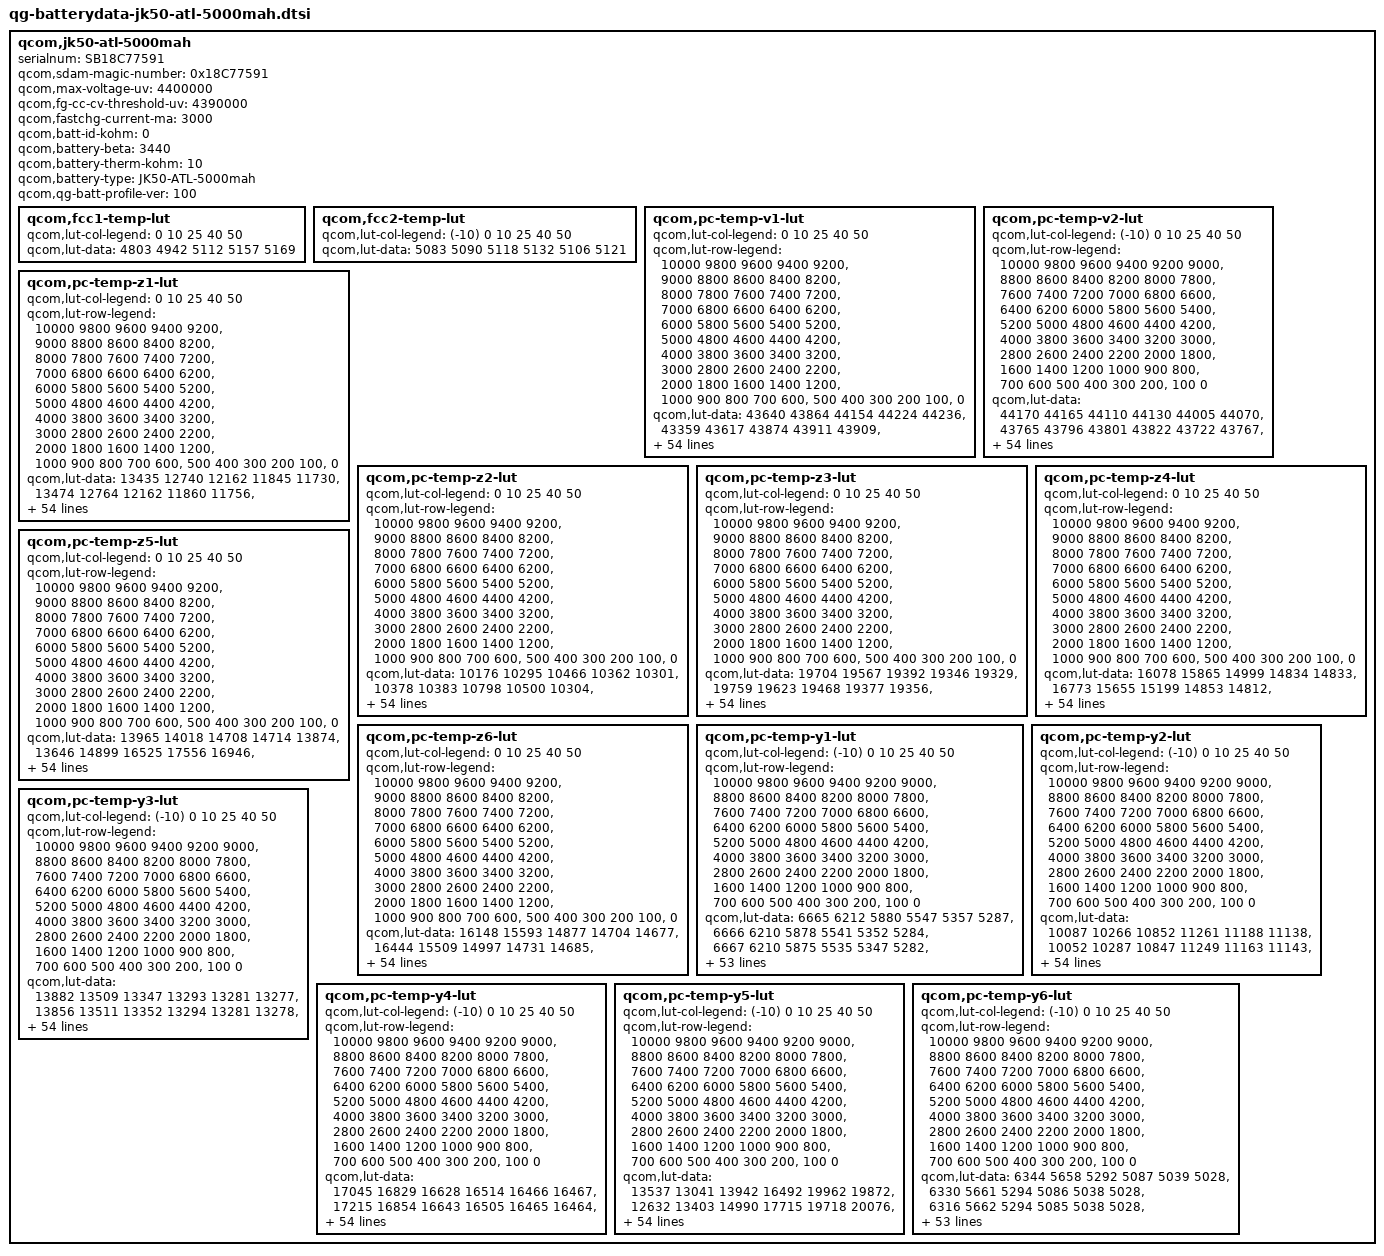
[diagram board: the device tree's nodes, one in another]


qcom,jk50-atl-5000mah {
    /* 4984199_Lenovo_Ibiza_5000mAH_PM7250B_averaged_MasterSlave_Dec17th2020 */
    serialnum = "SB18C77591";
    qcom,sdam-magic-number = <0x18C77591>;
    qcom,max-voltage-uv = <4400000>;
    qcom,fg-cc-cv-threshold-uv = <4390000>;
    qcom,fastchg-current-ma = <3000>;
    qcom,batt-id-kohm = <0>;
    qcom,battery-beta = <3440>;
    qcom,battery-therm-kohm = <10>;
    qcom,battery-type = "JK50-ATL-5000mah";
    qcom,qg-batt-profile-ver = <100>;

	qcom,fcc1-temp-lut {
		qcom,lut-col-legend = <0 10 25 40 50>;
		qcom,lut-data = <4803 4942 5112 5157 5169>;
	};

	qcom,fcc2-temp-lut {
		qcom,lut-col-legend = <(-10) 0 10 25 40 50>;
		qcom,lut-data = <5083 5090 5118 5132 5106 5121>;
	};

	qcom,pc-temp-v1-lut {
		qcom,lut-col-legend = <0 10 25 40 50>;
		qcom,lut-row-legend = <10000 9800 9600 9400 9200>,
			<9000 8800 8600 8400 8200>,
			<8000 7800 7600 7400 7200>,
			<7000 6800 6600 6400 6200>,
			<6000 5800 5600 5400 5200>,
			<5000 4800 4600 4400 4200>,
			<4000 3800 3600 3400 3200>,
			<3000 2800 2600 2400 2200>,
			<2000 1800 1600 1400 1200>,
			<1000 900 800 700 600>,
			<500 400 300 200 100>,
			<0>;
		qcom,lut-data = <43640 43864 44154 44224 44236>,
			<43359 43617 43874 43911 43909>,
			<43118 43373 43622 43662 43662>,
			<42886 43132 43397 43433 43432>,
			<42648 42893 43162 43205 43203>,
			<42411 42655 42918 42968 42971>,
			<42181 42419 42675 42731 42737>,
			<41959 42186 42435 42492 42501>,
			<41742 41959 42197 42254 42265>,
			<41532 41737 41963 42018 42029>,
			<41329 41519 41732 41784 41796>,
			<41130 41305 41506 41554 41565>,
			<40936 41098 41287 41330 41339>,
			<40742 40901 41073 41110 41115>,
			<40529 40708 40863 40897 40900>,
			<40281 40503 40657 40691 40694>,
			<40052 40272 40455 40489 40495>,
			<39883 40059 40250 40290 40302>,
			<39743 39894 40057 40097 40114>,
			<39611 39753 39892 39925 39938>,
			<39481 39613 39742 39776 39780>,
			<39358 39477 39577 39603 39603>,
			<39237 39334 39392 39336 39350>,
			<39120 39160 39194 39056 39082>,
			<39007 38964 38961 38883 38907>,
			<38896 38792 38723 38760 38784>,
			<38790 38635 38590 38655 38676>,
			<38691 38508 38516 38561 38575>,
			<38598 38431 38454 38476 38484>,
			<38512 38374 38389 38395 38396>,
			<38438 38327 38328 38320 38315>,
			<38371 38285 38273 38251 38241>,
			<38315 38248 38223 38188 38172>,
			<38269 38214 38175 38128 38106>,
			<38228 38183 38129 38069 38040>,
			<38189 38149 38085 38011 37974>,
			<38153 38115 38039 37957 37911>,
			<38112 38076 37994 37910 37854>,
			<38058 38018 37934 37850 37785>,
			<37991 37935 37848 37756 37687>,
			<37906 37836 37743 37642 37571>,
			<37783 37717 37630 37530 37456>,
			<37643 37579 37500 37408 37333>,
			<37483 37416 37341 37253 37180>,
			<37336 37268 37191 37103 37036>,
			<37255 37172 37089 37008 36945>,
			<37222 37144 37062 36978 36914>,
			<37192 37120 37043 36958 36896>,
			<37166 37105 37023 36941 36876>,
			<37112 37062 36982 36889 36813>,
			<36906 36840 36763 36650 36550>,
			<36454 36403 36336 36215 36108>,
			<35874 35828 35761 35637 35529>,
			<35087 35044 34973 34850 34734>,
			<33840 33803 33746 33622 33492>,
			<30000 30000 30000 30000 30000>;
	};

	qcom,pc-temp-v2-lut {
		qcom,lut-col-legend = <(-10) 0 10 25 40 50>;
		qcom,lut-row-legend = <10000 9800 9600 9400 9200 9000>,
			<8800 8600 8400 8200 8000 7800>,
			<7600 7400 7200 7000 6800 6600>,
			<6400 6200 6000 5800 5600 5400>,
			<5200 5000 4800 4600 4400 4200>,
			<4000 3800 3600 3400 3200 3000>,
			<2800 2600 2400 2200 2000 1800>,
			<1600 1400 1200 1000 900 800>,
			<700 600 500 400 300 200>,
			<100 0>;
		qcom,lut-data = <44170 44165 44110 44130 44005 44070>,
			<43765 43796 43801 43822 43722 43767>,
			<43400 43460 43513 43537 43454 43486>,
			<43080 43166 43247 43277 43204 43230>,
			<42796 42906 43003 43040 42971 42998>,
			<42537 42653 42761 42805 42738 42767>,
			<42310 42395 42514 42564 42500 42529>,
			<42090 42144 42270 42324 42261 42290>,
			<41826 41913 42032 42087 42026 42054>,
			<41525 41697 41798 41852 41793 41819>,
			<41297 41479 41569 41620 41563 41587>,
			<41169 41245 41342 41388 41335 41359>,
			<41045 41022 41124 41164 41112 41136>,
			<40828 40848 40928 40955 40900 40918>,
			<40504 40701 40744 40755 40696 40705>,
			<40180 40494 40537 40546 40490 40499>,
			<39836 40122 40297 40322 40278 40299>,
			<39535 39757 40054 40110 40077 40108>,
			<39347 39549 39821 39933 39905 39932>,
			<39205 39392 39595 39765 39743 39761>,
			<39047 39225 39385 39564 39559 39579>,
			<38862 39043 39188 39326 39343 39382>,
			<38687 38871 39008 39104 39131 39182>,
			<38537 38720 38844 38913 38930 38967>,
			<38402 38579 38694 38743 38743 38760>,
			<38298 38435 38561 38605 38598 38610>,
			<38217 38280 38439 38488 38481 38492>,
			<38147 38158 38330 38382 38377 38386>,
			<38082 38082 38232 38283 38280 38286>,
			<38022 38023 38139 38192 38191 38194>,
			<37964 37969 38050 38109 38111 38113>,
			<37908 37920 37965 38034 38039 38038>,
			<37852 37873 37897 37963 37969 37967>,
			<37794 37827 37845 37897 37904 37902>,
			<37736 37783 37801 37834 37837 37834>,
			<37676 37737 37759 37772 37755 37741>,
			<37613 37689 37719 37710 37663 37632>,
			<37547 37635 37674 37642 37572 37528>,
			<37475 37572 37620 37569 37483 37429>,
			<37400 37499 37557 37491 37395 37335>,
			<37328 37418 37475 37409 37312 37251>,
			<37257 37323 37373 37316 37224 37164>,
			<37182 37208 37244 37197 37105 37050>,
			<37108 37081 37108 37064 36975 36918>,
			<37035 36960 36959 36930 36857 36800>,
			<36935 36860 36879 36878 36821 36764>,
			<36883 36818 36850 36862 36807 36750>,
			<36821 36779 36824 36843 36791 36737>,
			<36745 36724 36781 36810 36760 36704>,
			<36623 36634 36699 36721 36652 36588>,
			<36390 36415 36472 36439 36293 36232>,
			<35985 35976 35996 35931 35776 35710>,
			<35372 35340 35336 35272 35089 35023>,
			<34458 34431 34436 34348 34107 34043>,
			<32987 32935 33138 33029 32671 32707>,
			<28320 27840 27870 27984 28103 27815>;
	};

	qcom,pc-temp-z1-lut {
		qcom,lut-col-legend = <0 10 25 40 50>;
		qcom,lut-row-legend = <10000 9800 9600 9400 9200>,
			<9000 8800 8600 8400 8200>,
			<8000 7800 7600 7400 7200>,
			<7000 6800 6600 6400 6200>,
			<6000 5800 5600 5400 5200>,
			<5000 4800 4600 4400 4200>,
			<4000 3800 3600 3400 3200>,
			<3000 2800 2600 2400 2200>,
			<2000 1800 1600 1400 1200>,
			<1000 900 800 700 600>,
			<500 400 300 200 100>,
			<0>;
		qcom,lut-data = <13435 12740 12162 11845 11730>,
			<13474 12764 12162 11860 11756>,
			<13445 12773 12156 11854 11754>,
			<13418 12765 12154 11847 11752>,
			<13418 12748 12150 11842 11751>,
			<13427 12731 12136 11836 11749>,
			<13431 12709 12121 11831 11748>,
			<13434 12694 12108 11828 11748>,
			<13434 12690 12095 11826 11749>,
			<13418 12686 12086 11825 11751>,
			<13377 12681 12078 11826 11755>,
			<13347 12669 12075 11828 11761>,
			<13337 12657 12076 11831 11765>,
			<13330 12638 12077 11836 11768>,
			<13316 12608 12076 11837 11769>,
			<13278 12593 12073 11836 11769>,
			<13245 12584 12072 11835 11770>,
			<13235 12580 12071 11835 11771>,
			<13226 12582 12071 11836 11772>,
			<13224 12587 12073 11838 11774>,
			<13229 12594 12079 11841 11775>,
			<13235 12603 12083 11843 11777>,
			<13227 12611 12086 11844 11777>,
			<13195 12618 12089 11845 11778>,
			<13173 12625 12092 11846 11779>,
			<13175 12632 12096 11848 11781>,
			<13183 12638 12099 11850 11784>,
			<13192 12642 12103 11854 11786>,
			<13204 12642 12107 11857 11789>,
			<13214 12641 12112 11861 11792>,
			<13220 12640 12117 11866 11795>,
			<13229 12642 12124 11870 11799>,
			<13237 12646 12131 11875 11803>,
			<13241 12654 12140 11880 11807>,
			<13242 12671 12148 11886 11812>,
			<13243 12683 12156 11892 11817>,
			<13245 12689 12164 11898 11822>,
			<13247 12694 12170 11903 11825>,
			<13251 12705 12178 11908 11829>,
			<13261 12726 12189 11914 11832>,
			<13274 12741 12199 11919 11836>,
			<13297 12747 12205 11924 11840>,
			<13326 12755 12210 11930 11844>,
			<13362 12774 12225 11936 11848>,
			<13381 12795 12239 11944 11852>,
			<13355 12786 12250 11951 11856>,
			<13331 12789 12246 11951 11856>,
			<13311 12788 12245 11952 11858>,
			<13321 12783 12251 11954 11861>,
			<13369 12798 12256 11959 11864>,
			<13378 12821 12262 11965 11869>,
			<13406 12809 12280 11975 11876>,
			<13378 12851 12295 11985 11887>,
			<13451 12865 12319 12005 11904>,
			<13451 12865 12319 12005 11904>,
			<13451 12865 12319 12005 11904>;
	};

	qcom,pc-temp-z2-lut {
		qcom,lut-col-legend = <0 10 25 40 50>;
		qcom,lut-row-legend = <10000 9800 9600 9400 9200>,
			<9000 8800 8600 8400 8200>,
			<8000 7800 7600 7400 7200>,
			<7000 6800 6600 6400 6200>,
			<6000 5800 5600 5400 5200>,
			<5000 4800 4600 4400 4200>,
			<4000 3800 3600 3400 3200>,
			<3000 2800 2600 2400 2200>,
			<2000 1800 1600 1400 1200>,
			<1000 900 800 700 600>,
			<500 400 300 200 100>,
			<0>;
		qcom,lut-data = <10176 10295 10466 10362 10301>,
			<10378 10383 10798 10500 10304>,
			<10380 10420 10592 10668 10626>,
			<10378 10401 10568 10655 10663>,
			<10367 10367 10539 10637 10674>,
			<10346 10351 10505 10607 10655>,
			<10337 10342 10473 10567 10610>,
			<10343 10336 10445 10533 10568>,
			<10351 10332 10420 10501 10522>,
			<10355 10329 10396 10474 10489>,
			<10357 10322 10371 10449 10470>,
			<10355 10309 10361 10432 10457>,
			<10345 10298 10362 10430 10461>,
			<10325 10342 10366 10436 10479>,
			<10304 10422 10376 10443 10481>,
			<10276 10431 10403 10466 10386>,
			<10256 10353 10446 10482 10295>,
			<10254 10295 10697 10477 10305>,
			<10254 10307 10942 10462 10340>,
			<10254 10335 10852 10440 10369>,
			<10254 10362 10592 10399 10388>,
			<10254 10387 10522 10377 10420>,
			<10251 10414 10594 10546 10600>,
			<10243 10450 10651 10771 10838>,
			<10238 10490 10641 10731 10809>,
			<10240 10505 10617 10495 10538>,
			<10244 10507 10602 10393 10404>,
			<10250 10508 10588 10403 10423>,
			<10259 10508 10580 10419 10454>,
			<10270 10508 10596 10434 10481>,
			<10280 10509 10624 10453 10509>,
			<10291 10510 10637 10484 10514>,
			<10302 10511 10644 10543 10486>,
			<10312 10514 10649 10602 10458>,
			<10322 10520 10657 10643 10461>,
			<10332 10526 10665 10675 10476>,
			<10341 10532 10668 10670 10476>,
			<10352 10538 10672 10627 10462>,
			<10368 10548 10677 10604 10460>,
			<10388 10561 10698 10666 10510>,
			<10409 10576 10720 10742 10572>,
			<10431 10588 10728 10742 10585>,
			<10467 10604 10732 10724 10582>,
			<10540 10636 10740 10719 10575>,
			<10927 10834 10788 10701 10573>,
			<10827 10953 10874 10643 10585>,
			<10714 10955 10855 10653 10594>,
			<10710 10971 10840 10619 10570>,
			<10612 11105 10843 10647 10587>,
			<10565 11219 10879 10760 10685>,
			<10513 11089 10912 10734 10594>,
			<10504 11071 10878 10516 10330>,
			<10298 10924 10757 10430 10257>,
			<10059 10722 10666 10396 10206>,
			<10059 10722 10666 10396 10206>,
			<10059 10722 10666 10396 10206>;
	};

	qcom,pc-temp-z3-lut {
		qcom,lut-col-legend = <0 10 25 40 50>;
		qcom,lut-row-legend = <10000 9800 9600 9400 9200>,
			<9000 8800 8600 8400 8200>,
			<8000 7800 7600 7400 7200>,
			<7000 6800 6600 6400 6200>,
			<6000 5800 5600 5400 5200>,
			<5000 4800 4600 4400 4200>,
			<4000 3800 3600 3400 3200>,
			<3000 2800 2600 2400 2200>,
			<2000 1800 1600 1400 1200>,
			<1000 900 800 700 600>,
			<500 400 300 200 100>,
			<0>;
		qcom,lut-data = <19704 19567 19392 19346 19329>,
			<19759 19623 19468 19377 19356>,
			<19701 19650 19488 19411 19385>,
			<19648 19652 19490 19417 19397>,
			<19638 19654 19492 19420 19403>,
			<19634 19653 19494 19422 19406>,
			<19633 19646 19495 19423 19408>,
			<19636 19636 19492 19423 19409>,
			<19640 19626 19485 19421 19408>,
			<19643 19616 19480 19419 19408>,
			<19646 19609 19475 19418 19406>,
			<19649 19604 19469 19415 19403>,
			<19650 19600 19464 19410 19400>,
			<19651 19596 19458 19400 19394>,
			<19655 19590 19449 19394 19388>,
			<19671 19585 19439 19390 19379>,
			<19685 19570 19434 19386 19370>,
			<19680 19554 19440 19384 19366>,
			<19667 19541 19446 19381 19363>,
			<19658 19527 19438 19375 19359>,
			<19653 19520 19421 19365 19352>,
			<19650 19517 19415 19359 19348>,
			<19652 19515 19423 19369 19354>,
			<19664 19523 19429 19381 19361>,
			<19674 19541 19429 19379 19359>,
			<19682 19549 19428 19364 19342>,
			<19689 19549 19426 19354 19331>,
			<19691 19549 19420 19350 19327>,
			<19689 19548 19416 19348 19326>,
			<19687 19544 19415 19348 19327>,
			<19683 19539 19415 19351 19330>,
			<19678 19534 19415 19353 19334>,
			<19671 19528 19416 19358 19341>,
			<19663 19523 19417 19363 19348>,
			<19653 19518 19419 19370 19354>,
			<19642 19514 19421 19377 19359>,
			<19631 19510 19421 19376 19359>,
			<19621 19506 19419 19368 19352>,
			<19611 19504 19417 19363 19347>,
			<19602 19502 19415 19363 19345>,
			<19595 19500 19413 19363 19344>,
			<19591 19495 19409 19362 19344>,
			<19584 19488 19405 19359 19347>,
			<19568 19482 19401 19358 19348>,
			<19503 19453 19392 19355 19347>,
			<19369 19424 19379 19342 19334>,
			<19330 19413 19374 19340 19332>,
			<19324 19410 19370 19339 19325>,
			<19309 19353 19370 19332 19321>,
			<19306 19331 19352 19324 19317>,
			<19310 19401 19354 19329 19334>,
			<19329 19391 19351 19355 19356>,
			<19336 19363 19351 19359 19355>,
			<19342 19322 19350 19351 19351>,
			<19342 19322 19350 19351 19351>,
			<19342 19322 19350 19351 19351>;
	};

	qcom,pc-temp-z4-lut {
		qcom,lut-col-legend = <0 10 25 40 50>;
		qcom,lut-row-legend = <10000 9800 9600 9400 9200>,
			<9000 8800 8600 8400 8200>,
			<8000 7800 7600 7400 7200>,
			<7000 6800 6600 6400 6200>,
			<6000 5800 5600 5400 5200>,
			<5000 4800 4600 4400 4200>,
			<4000 3800 3600 3400 3200>,
			<3000 2800 2600 2400 2200>,
			<2000 1800 1600 1400 1200>,
			<1000 900 800 700 600>,
			<500 400 300 200 100>,
			<0>;
		qcom,lut-data = <16078 15865 14999 14834 14833>,
			<16773 15655 15199 14853 14812>,
			<16522 15477 15191 14942 14872>,
			<16217 15324 15060 14899 14849>,
			<16011 15195 14973 14855 14820>,
			<15829 15100 14917 14827 14800>,
			<15678 15026 14873 14804 14781>,
			<15552 14967 14838 14784 14765>,
			<15445 14920 14809 14766 14750>,
			<15360 14882 14786 14750 14736>,
			<15291 14849 14765 14733 14722>,
			<15228 14821 14747 14719 14709>,
			<15164 14796 14730 14710 14700>,
			<15105 14764 14716 14703 14693>,
			<15061 14732 14709 14696 14689>,
			<15028 14723 14706 14688 14687>,
			<14999 14729 14700 14681 14686>,
			<14971 14733 14679 14676 14682>,
			<14944 14727 14659 14672 14675>,
			<14919 14718 14657 14669 14671>,
			<14896 14710 14662 14665 14667>,
			<14874 14702 14669 14664 14665>,
			<14849 14696 14676 14699 14696>,
			<14820 14700 14688 14752 14749>,
			<14794 14713 14728 14776 14775>,
			<14773 14727 14787 14792 14792>,
			<14755 14750 14800 14796 14797>,
			<14746 14767 14790 14790 14792>,
			<14742 14766 14777 14780 14782>,
			<14739 14757 14766 14769 14772>,
			<14737 14747 14753 14755 14757>,
			<14736 14738 14740 14740 14741>,
			<14735 14729 14727 14723 14721>,
			<14732 14720 14715 14707 14702>,
			<14729 14712 14702 14690 14685>,
			<14727 14704 14690 14677 14672>,
			<14725 14697 14683 14672 14669>,
			<14723 14691 14678 14671 14668>,
			<14720 14690 14676 14670 14668>,
			<14717 14689 14682 14678 14678>,
			<14715 14689 14688 14687 14691>,
			<14713 14690 14687 14687 14690>,
			<14710 14691 14686 14684 14682>,
			<14702 14688 14685 14683 14682>,
			<14692 14673 14677 14679 14678>,
			<14803 14668 14658 14664 14662>,
			<14844 14673 14654 14659 14659>,
			<14847 14670 14648 14648 14652>,
			<14858 14726 14637 14637 14634>,
			<14852 14745 14650 14638 14630>,
			<14846 14671 14667 14660 14646>,
			<14847 14699 14684 14651 14644>,
			<14858 14739 14690 14653 14649>,
			<14870 14793 14696 14665 14658>,
			<14870 14793 14696 14665 14658>,
			<14870 14793 14696 14665 14658>;
	};

	qcom,pc-temp-z5-lut {
		qcom,lut-col-legend = <0 10 25 40 50>;
		qcom,lut-row-legend = <10000 9800 9600 9400 9200>,
			<9000 8800 8600 8400 8200>,
			<8000 7800 7600 7400 7200>,
			<7000 6800 6600 6400 6200>,
			<6000 5800 5600 5400 5200>,
			<5000 4800 4600 4400 4200>,
			<4000 3800 3600 3400 3200>,
			<3000 2800 2600 2400 2200>,
			<2000 1800 1600 1400 1200>,
			<1000 900 800 700 600>,
			<500 400 300 200 100>,
			<0>;
		qcom,lut-data = <13965 14018 14708 14714 13874>,
			<13646 14899 16525 17556 16946>,
			<13758 15591 17147 18406 18349>,
			<13933 16076 17498 19062 19760>,
			<14180 16479 17982 19635 20965>,
			<14542 16905 18692 20075 21571>,
			<14869 17340 19325 20467 22024>,
			<15158 17765 19790 20879 22559>,
			<15410 18147 20228 21296 23152>,
			<15590 18546 20621 21841 23842>,
			<15734 19134 21231 22865 24749>,
			<15839 20132 21929 23808 25769>,
			<15894 21138 22987 24072 26838>,
			<15940 23127 23946 24193 27981>,
			<16100 25816 24050 24468 28307>,
			<16736 26283 23945 25312 27155>,
			<17256 25497 24227 26452 26035>,
			<17213 24967 31015 28040 26735>,
			<17054 24850 38195 29709 28556>,
			<16995 24655 37014 29924 29628>,
			<17208 24696 32389 29329 30074>,
			<17630 26253 32949 29010 30757>,
			<18358 29283 45186 39916 35874>,
			<20045 40149 55207 54482 42763>,
			<22268 60347 54498 51773 40945>,
			<25604 65535 51766 35614 28789>,
			<29844 65535 47811 26141 21313>,
			<33454 63513 40372 23210 19427>,
			<36965 59705 34528 21662 18465>,
			<39497 53865 32081 21269 18364>,
			<40530 49066 30555 21058 18358>,
			<41212 45483 30389 21122 18493>,
			<41350 42578 30613 22319 19811>,
			<39740 40368 30999 24348 21987>,
			<37257 38525 33398 29507 26441>,
			<35146 37656 36902 35990 31960>,
			<32574 37358 39259 36772 32989>,
			<30651 37201 41389 35012 32705>,
			<29600 37605 42132 34045 32265>,
			<28873 39120 41386 34290 31436>,
			<28896 39890 40045 34586 30180>,
			<30293 37272 36996 32363 28281>,
			<31856 34776 32519 26956 26046>,
			<33377 34945 31446 26600 26436>,
			<31464 35539 31361 26689 26668>,
			<15864 30495 31786 24225 23147>,
			<13240 25744 29517 23582 22029>,
			<13028 25005 27866 24554 20780>,
			<12594 15928 29916 24017 23361>,
			<12573 14407 23543 22150 22767>,
			<12817 24233 21320 19790 23926>,
			<13203 19238 18059 22759 25956>,
			<13000 15863 17006 21908 22723>,
			<12785 13018 16149 18004 18844>,
			<12785 13018 16149 18004 18844>,
			<12785 13018 16149 18004 18844>;
	};

	qcom,pc-temp-z6-lut {
		qcom,lut-col-legend = <0 10 25 40 50>;
		qcom,lut-row-legend = <10000 9800 9600 9400 9200>,
			<9000 8800 8600 8400 8200>,
			<8000 7800 7600 7400 7200>,
			<7000 6800 6600 6400 6200>,
			<6000 5800 5600 5400 5200>,
			<5000 4800 4600 4400 4200>,
			<4000 3800 3600 3400 3200>,
			<3000 2800 2600 2400 2200>,
			<2000 1800 1600 1400 1200>,
			<1000 900 800 700 600>,
			<500 400 300 200 100>,
			<0>;
		qcom,lut-data = <16148 15593 14877 14704 14677>,
			<16444 15509 14997 14731 14685>,
			<16268 15429 15000 14784 14724>,
			<16060 15350 14940 14769 14720>,
			<15933 15277 14900 14752 14713>,
			<15827 15218 14874 14740 14707>,
			<15741 15170 14852 14730 14700>,
			<15670 15129 14831 14721 14693>,
			<15612 15095 14814 14713 14687>,
			<15565 15065 14799 14705 14681>,
			<15528 15042 14786 14697 14676>,
			<15491 15024 14774 14691 14670>,
			<15445 15007 14764 14683 14664>,
			<15400 14983 14754 14676 14658>,
			<15371 14959 14746 14670 14653>,
			<15354 14943 14739 14663 14647>,
			<15338 14935 14732 14658 14642>,
			<15318 14927 14727 14654 14637>,
			<15297 14917 14722 14651 14633>,
			<15279 14908 14716 14646 14628>,
			<15264 14902 14710 14639 14623>,
			<15251 14899 14709 14635 14620>,
			<15241 14897 14715 14657 14638>,
			<15232 14903 14726 14687 14666>,
			<15225 14919 14745 14691 14670>,
			<15219 14933 14769 14691 14669>,
			<15214 14944 14774 14690 14668>,
			<15211 14952 14768 14687 14665>,
			<15209 14951 14762 14681 14660>,
			<15207 14946 14757 14677 14656>,
			<15206 14941 14752 14673 14652>,
			<15205 14935 14748 14669 14649>,
			<15203 14930 14744 14665 14644>,
			<15200 14926 14740 14662 14640>,
			<15195 14922 14738 14660 14638>,
			<15191 14919 14735 14658 14635>,
			<15187 14917 14733 14656 14633>,
			<15185 14916 14732 14651 14629>,
			<15186 14916 14731 14650 14628>,
			<15189 14920 14734 14653 14631>,
			<15193 14923 14738 14658 14636>,
			<15200 14926 14738 14658 14636>,
			<15203 14928 14737 14656 14635>,
			<15205 14930 14737 14656 14636>,
			<15180 14920 14733 14654 14634>,
			<15168 14907 14721 14641 14621>,
			<15165 14903 14717 14638 14619>,
			<15163 14901 14712 14633 14612>,
			<15161 14897 14708 14625 14603>,
			<15163 14898 14706 14622 14599>,
			<15171 14907 14716 14635 14615>,
			<15189 14920 14726 14647 14629>,
			<15209 14931 14733 14653 14634>,
			<15237 14949 14742 14658 14639>,
			<15237 14949 14742 14658 14639>,
			<15237 14949 14742 14658 14639>;
	};

	qcom,pc-temp-y1-lut {
		qcom,lut-col-legend = <(-10) 0 10 25 40 50>;
		qcom,lut-row-legend = <10000 9800 9600 9400 9200 9000>,
			<8800 8600 8400 8200 8000 7800>,
			<7600 7400 7200 7000 6800 6600>,
			<6400 6200 6000 5800 5600 5400>,
			<5200 5000 4800 4600 4400 4200>,
			<4000 3800 3600 3400 3200 3000>,
			<2800 2600 2400 2200 2000 1800>,
			<1600 1400 1200 1000 900 800>,
			<700 600 500 400 300 200>,
			<100 0>;
		qcom,lut-data = <6665 6212 5880 5547 5357 5287>,
			<6666 6210 5878 5541 5352 5284>,
			<6667 6210 5875 5535 5347 5282>,
			<6668 6210 5872 5530 5342 5279>,
			<6669 6212 5869 5524 5338 5277>,
			<6669 6214 5867 5519 5334 5275>,
			<6672 6217 5866 5514 5331 5272>,
			<6676 6221 5865 5510 5328 5271>,
			<6676 6220 5861 5505 5325 5269>,
			<6671 6218 5853 5502 5322 5268>,
			<6670 6217 5849 5498 5319 5267>,
			<6670 6217 5849 5495 5318 5266>,
			<6671 6218 5849 5493 5316 5264>,
			<6673 6220 5847 5490 5315 5263>,
			<6675 6226 5844 5488 5314 5263>,
			<6678 6231 5843 5488 5313 5262>,
			<6685 6238 5847 5488 5313 5263>,
			<6691 6242 5851 5488 5313 5263>,
			<6688 6243 5853 5489 5313 5264>,
			<6683 6243 5855 5490 5314 5264>,
			<6681 6243 5855 5492 5315 5265>,
			<6681 6243 5854 5492 5315 5266>,
			<6680 6242 5854 5494 5316 5266>,
			<6670 6241 5854 5496 5318 5267>,
			<6648 6238 5853 5500 5319 5268>,
			<6643 6238 5855 5503 5321 5270>,
			<6656 6237 5860 5506 5324 5271>,
			<6665 6237 5864 5510 5327 5273>,
			<6657 6236 5867 5515 5330 5275>,
			<6646 6235 5869 5519 5333 5278>,
			<6646 6235 5871 5524 5336 5280>,
			<6657 6237 5874 5529 5340 5283>,
			<6662 6239 5875 5534 5343 5286>,
			<6661 6233 5875 5539 5347 5288>,
			<6659 6226 5876 5544 5350 5290>,
			<6656 6225 5878 5548 5353 5292>,
			<6653 6225 5881 5552 5355 5294>,
			<6651 6225 5883 5554 5357 5295>,
			<6649 6224 5887 5556 5358 5297>,
			<6647 6222 5889 5558 5360 5299>,
			<6642 6223 5889 5559 5362 5300>,
			<6635 6225 5890 5561 5363 5301>,
			<6633 6225 5899 5568 5366 5303>,
			<6630 6226 5903 5578 5370 5305>,
			<6635 6241 5910 5579 5374 5310>,
			<6682 6248 5913 5589 5379 5313>,
			<6682 6244 5914 5592 5380 5312>,
			<6688 6258 5915 5595 5379 5313>,
			<6690 6241 5916 5595 5379 5312>,
			<6693 6238 5919 5595 5380 5313>,
			<6708 6254 5928 5599 5384 5317>,
			<6703 6268 5930 5613 5391 5323>,
			<6708 6264 5946 5634 5403 5332>,
			<6718 6292 5969 5656 5417 5343>,
			<6718 6292 5969 5656 5417 5343>,
			<6718 6292 5969 5656 5417 5343>;
	};

	qcom,pc-temp-y2-lut {
		qcom,lut-col-legend = <(-10) 0 10 25 40 50>;
		qcom,lut-row-legend = <10000 9800 9600 9400 9200 9000>,
			<8800 8600 8400 8200 8000 7800>,
			<7600 7400 7200 7000 6800 6600>,
			<6400 6200 6000 5800 5600 5400>,
			<5200 5000 4800 4600 4400 4200>,
			<4000 3800 3600 3400 3200 3000>,
			<2800 2600 2400 2200 2000 1800>,
			<1600 1400 1200 1000 900 800>,
			<700 600 500 400 300 200>,
			<100 0>;
		qcom,lut-data = <10087 10266 10852 11261 11188 11138>,
			<10052 10287 10847 11249 11163 11143>,
			<10042 10317 10841 11233 11125 11132>,
			<10053 10350 10837 11212 11085 11111>,
			<10077 10378 10832 11190 11052 11083>,
			<10109 10396 10828 11165 11037 11054>,
			<10152 10410 10823 11133 11034 11009>,
			<10213 10421 10820 11104 11032 10966>,
			<10327 10421 10823 11090 11016 10951>,
			<10519 10421 10828 11080 10980 10946>,
			<10598 10444 10832 11078 10959 10946>,
			<10539 10596 10837 11093 10957 10956>,
			<10473 10761 10845 11108 10964 10962>,
			<10528 10792 10879 11106 10992 10950>,
			<10701 10796 10957 11102 11047 10932>,
			<10738 10796 11025 11110 11094 10936>,
			<10220 10818 11097 11169 11133 11022>,
			<9713 10852 11141 11242 11176 11116>,
			<9684 10908 11142 11318 11245 11161>,
			<9680 10995 11140 11385 11334 11200>,
			<9677 11059 11146 11387 11390 11280>,
			<9674 11114 11173 11342 11432 11448>,
			<9672 11143 11203 11317 11452 11540>,
			<9671 11123 11230 11336 11389 11391>,
			<9670 11065 11260 11366 11285 11185>,
			<9669 10962 11291 11388 11261 11165>,
			<9668 10695 11323 11412 11276 11201>,
			<9667 10488 11347 11437 11285 11239>,
			<9666 10429 11365 11472 11313 11281>,
			<9665 10388 11377 11504 11361 11325>,
			<9664 10285 11376 11533 11406 11355>,
			<9664 9941 11370 11567 11480 11379>,
			<9663 9740 11361 11585 11523 11413>,
			<9663 9711 11349 11594 11547 11492>,
			<9662 9694 11332 11598 11564 11553>,
			<9662 9687 11306 11593 11560 11520>,
			<9661 9682 11270 11579 11541 11436>,
			<9661 9678 11235 11561 11514 11396>,
			<9661 9674 11203 11534 11461 11373>,
			<9660 9671 11165 11513 11416 11350>,
			<9660 9668 11116 11504 11412 11304>,
			<9660 9666 11046 11490 11416 11265>,
			<9659 9664 10578 11436 11390 11342>,
			<9659 9662 10706 11422 11357 11296>,
			<9659 9661 10625 11393 11319 11214>,
			<9658 9660 10448 11304 11266 11043>,
			<9658 9659 10347 11291 11220 11007>,
			<9658 9658 10254 11296 11245 11058>,
			<9658 9658 10200 11282 11271 11119>,
			<9658 9657 10160 11282 11293 11095>,
			<9657 9657 10141 11250 11192 10938>,
			<9656 9656 9937 11147 11126 10882>,
			<9656 9656 9686 11046 11041 10805>,
			<9653 9655 9668 10946 10902 10690>,
			<9653 9655 9668 10946 10902 10690>,
			<9653 9655 9668 10946 10902 10690>;
	};

	qcom,pc-temp-y3-lut {
		qcom,lut-col-legend = <(-10) 0 10 25 40 50>;
		qcom,lut-row-legend = <10000 9800 9600 9400 9200 9000>,
			<8800 8600 8400 8200 8000 7800>,
			<7600 7400 7200 7000 6800 6600>,
			<6400 6200 6000 5800 5600 5400>,
			<5200 5000 4800 4600 4400 4200>,
			<4000 3800 3600 3400 3200 3000>,
			<2800 2600 2400 2200 2000 1800>,
			<1600 1400 1200 1000 900 800>,
			<700 600 500 400 300 200>,
			<100 0>;
		qcom,lut-data = <13882 13509 13347 13293 13281 13277>,
			<13856 13511 13352 13294 13281 13278>,
			<13827 13511 13356 13296 13282 13278>,
			<13799 13512 13360 13298 13282 13279>,
			<13778 13512 13363 13299 13282 13279>,
			<13768 13511 13364 13300 13283 13280>,
			<13770 13506 13363 13300 13283 13280>,
			<13772 13500 13362 13300 13284 13281>,
			<13751 13504 13361 13300 13284 13281>,
			<13676 13522 13361 13301 13285 13282>,
			<13617 13530 13361 13302 13285 13282>,
			<13559 13493 13361 13301 13285 13283>,
			<13512 13450 13361 13300 13286 13283>,
			<13515 13443 13361 13302 13287 13284>,
			<13531 13442 13361 13306 13291 13284>,
			<13535 13441 13360 13307 13292 13284>,
			<13496 13432 13357 13306 13292 13287>,
			<13458 13422 13354 13305 13291 13289>,
			<13461 13413 13350 13306 13292 13290>,
			<13472 13402 13346 13308 13293 13290>,
			<13475 13390 13341 13307 13293 13290>,
			<13472 13376 13335 13303 13291 13289>,
			<13468 13364 13331 13298 13288 13287>,
			<13461 13360 13327 13295 13285 13283>,
			<13452 13356 13324 13293 13282 13278>,
			<13452 13351 13322 13292 13281 13278>,
			<13464 13340 13320 13292 13280 13278>,
			<13481 13331 13318 13292 13280 13278>,
			<13502 13328 13317 13292 13279 13277>,
			<13529 13327 13316 13292 13278 13276>,
			<13554 13327 13315 13292 13279 13276>,
			<13577 13332 13313 13292 13280 13277>,
			<13601 13338 13313 13292 13281 13277>,
			<13627 13347 13313 13292 13281 13278>,
			<13655 13359 13314 13292 13282 13279>,
			<13686 13369 13315 13292 13282 13279>,
			<13720 13381 13318 13293 13281 13278>,
			<13755 13395 13320 13293 13281 13278>,
			<13790 13419 13322 13292 13280 13277>,
			<13828 13449 13323 13291 13279 13277>,
			<13870 13481 13324 13291 13280 13279>,
			<13914 13519 13325 13291 13281 13280>,
			<13954 13564 13320 13292 13281 13280>,
			<13999 13621 13324 13293 13280 13279>,
			<14018 13654 13319 13290 13277 13276>,
			<14052 13726 13325 13294 13284 13283>,
			<14101 13790 13331 13296 13287 13285>,
			<14154 13861 13343 13301 13292 13290>,
			<14219 13931 13356 13306 13295 13291>,
			<14295 14011 13366 13309 13295 13289>,
			<14384 14079 13388 13307 13289 13285>,
			<14510 14172 13403 13307 13291 13286>,
			<14708 14327 13453 13315 13296 13290>,
			<15191 14518 13560 13326 13302 13297>,
			<15191 14518 13560 13326 13302 13297>,
			<15191 14518 13560 13326 13302 13297>;
	};

	qcom,pc-temp-y4-lut {
		qcom,lut-col-legend = <(-10) 0 10 25 40 50>;
		qcom,lut-row-legend = <10000 9800 9600 9400 9200 9000>,
			<8800 8600 8400 8200 8000 7800>,
			<7600 7400 7200 7000 6800 6600>,
			<6400 6200 6000 5800 5600 5400>,
			<5200 5000 4800 4600 4400 4200>,
			<4000 3800 3600 3400 3200 3000>,
			<2800 2600 2400 2200 2000 1800>,
			<1600 1400 1200 1000 900 800>,
			<700 600 500 400 300 200>,
			<100 0>;
		qcom,lut-data = <17045 16829 16628 16514 16466 16467>,
			<17215 16854 16643 16505 16465 16464>,
			<17321 16892 16653 16498 16464 16462>,
			<17378 16932 16660 16494 16463 16461>,
			<17401 16963 16663 16491 16463 16460>,
			<17405 16975 16664 16491 16463 16459>,
			<17356 16975 16659 16493 16464 16460>,
			<17286 16973 16654 16496 16466 16461>,
			<17268 16965 16654 16499 16469 16462>,
			<17291 16939 16658 16504 16474 16465>,
			<17336 16930 16663 16509 16478 16468>,
			<17501 17011 16668 16519 16484 16471>,
			<17663 17108 16676 16530 16490 16475>,
			<17582 17151 16707 16539 16494 16480>,
			<17303 17214 16766 16549 16499 16486>,
			<17153 17217 16787 16563 16505 16491>,
			<17107 17013 16786 16586 16514 16494>,
			<17074 16824 16780 16609 16526 16499>,
			<17043 16816 16744 16632 16547 16511>,
			<17004 16818 16678 16651 16571 16527>,
			<16955 16815 16634 16644 16574 16537>,
			<16884 16790 16604 16589 16561 16543>,
			<16823 16757 16582 16539 16541 16545>,
			<16791 16723 16567 16505 16506 16514>,
			<16767 16686 16557 16482 16470 16470>,
			<16762 16656 16553 16480 16464 16464>,
			<16761 16619 16550 16481 16465 16464>,
			<16760 16599 16548 16482 16468 16464>,
			<16758 16605 16546 16487 16474 16469>,
			<16756 16618 16544 16493 16482 16477>,
			<16756 16630 16536 16499 16491 16486>,
			<16757 16647 16522 16507 16501 16495>,
			<16759 16661 16517 16513 16509 16504>,
			<16762 16671 16523 16518 16516 16514>,
			<16765 16680 16532 16521 16520 16520>,
			<16765 16692 16542 16518 16514 16512>,
			<16762 16708 16555 16512 16495 16493>,
			<16760 16718 16567 16506 16483 16480>,
			<16761 16719 16580 16497 16475 16471>,
			<16762 16717 16589 16493 16471 16467>,
			<16766 16715 16591 16497 16475 16473>,
			<16776 16712 16593 16501 16481 16480>,
			<16798 16704 16608 16502 16479 16479>,
			<16822 16692 16595 16498 16470 16468>,
			<16814 16677 16566 16478 16456 16447>,
			<16808 16683 16582 16492 16466 16460>,
			<16823 16702 16601 16507 16482 16486>,
			<16846 16731 16630 16527 16514 16524>,
			<16873 16772 16669 16562 16554 16560>,
			<16887 16823 16721 16585 16558 16556>,
			<16879 16834 16726 16556 16484 16483>,
			<16855 16809 16718 16536 16480 16475>,
			<16854 16806 16755 16559 16489 16480>,
			<16946 16831 16831 16612 16526 16507>,
			<16946 16831 16831 16612 16526 16507>,
			<16946 16831 16831 16612 16526 16507>;
	};

	qcom,pc-temp-y5-lut {
		qcom,lut-col-legend = <(-10) 0 10 25 40 50>;
		qcom,lut-row-legend = <10000 9800 9600 9400 9200 9000>,
			<8800 8600 8400 8200 8000 7800>,
			<7600 7400 7200 7000 6800 6600>,
			<6400 6200 6000 5800 5600 5400>,
			<5200 5000 4800 4600 4400 4200>,
			<4000 3800 3600 3400 3200 3000>,
			<2800 2600 2400 2200 2000 1800>,
			<1600 1400 1200 1000 900 800>,
			<700 600 500 400 300 200>,
			<100 0>;
		qcom,lut-data = <13537 13041 13942 16492 19962 19872>,
			<12632 13403 14990 17715 19718 20076>,
			<12277 13824 16013 18441 19392 20087>,
			<12343 14235 16884 18795 19003 19973>,
			<12702 14567 17476 18902 18569 19799>,
			<13235 14751 17661 18872 18107 19626>,
			<14566 14795 17462 18092 17567 19192>,
			<15935 14834 17134 17035 17015 18592>,
			<15684 15418 16828 16581 16557 18040>,
			<14180 17131 16452 16290 16138 17339>,
			<13386 17843 16221 15893 15717 16774>,
			<13727 15905 16094 15089 15189 16379>,
			<14531 13767 15962 14493 14826 16014>,
			<16734 14721 15720 14528 15002 15543>,
			<21108 17983 15399 14652 15490 15062>,
			<22432 19601 15544 14691 15606 14987>,
			<17644 19327 17832 14598 15089 15408>,
			<13002 18814 20082 14542 14648 15740>,
			<13366 18705 20924 15719 14756 15690>,
			<14738 18583 21486 18084 15134 15595>,
			<15204 18575 21521 19969 16087 15998>,
			<15046 18631 21171 21777 19359 18352>,
			<14747 18760 20805 22533 21537 19818>,
			<13968 19942 20485 21616 21291 19789>,
			<12797 21973 20230 20405 20744 19719>,
			<12408 21831 20143 20165 20127 19570>,
			<12313 17705 19904 20237 19134 19173>,
			<12286 14535 19871 20225 18219 18622>,
			<12407 14056 20750 20078 17377 17444>,
			<12636 13768 21727 19994 16740 16394>,
			<12818 13487 21583 20156 16826 16339>,
			<12981 13176 20824 20548 17455 16434>,
			<13090 13103 20476 21024 18194 16635>,
			<13155 13277 20126 21695 19082 17553>,
			<13203 13456 19829 22392 20001 18667>,
			<13257 13514 19924 23097 20788 19501>,
			<13402 13617 20117 23721 21496 20211>,
			<13469 13696 20167 23626 21593 20320>,
			<13322 13881 20120 22371 20352 19957>,
			<13101 14091 20037 21056 19168 19621>,
			<12979 14161 19777 19920 19080 19814>,
			<12886 14196 19233 19235 19200 20301>,
			<12645 14030 16891 19098 18966 20705>,
			<12508 13695 17455 19234 19257 20673>,
			<12984 13445 16131 19033 16627 17695>,
			<13068 13342 15585 18194 17500 18457>,
			<13292 13341 15134 17620 17914 17313>,
			<13374 13596 15203 17573 18295 17328>,
			<13599 13679 15120 17779 17991 16698>,
			<13923 14028 15394 17994 17720 16415>,
			<13876 13969 16187 18886 18479 17007>,
			<13468 13564 15220 19380 19969 17670>,
			<13058 13446 13811 19982 21375 18479>,
			<12417 13265 13683 21736 24001 22751>,
			<12417 13265 13683 21736 24001 22751>,
			<12417 13265 13683 21736 24001 22751>;
	};

	qcom,pc-temp-y6-lut {
		qcom,lut-col-legend = <(-10) 0 10 25 40 50>;
		qcom,lut-row-legend = <10000 9800 9600 9400 9200 9000>,
			<8800 8600 8400 8200 8000 7800>,
			<7600 7400 7200 7000 6800 6600>,
			<6400 6200 6000 5800 5600 5400>,
			<5200 5000 4800 4600 4400 4200>,
			<4000 3800 3600 3400 3200 3000>,
			<2800 2600 2400 2200 2000 1800>,
			<1600 1400 1200 1000 900 800>,
			<700 600 500 400 300 200>,
			<100 0>;
		qcom,lut-data = <6344 5658 5292 5087 5039 5028>,
			<6330 5661 5294 5086 5038 5028>,
			<6316 5662 5294 5085 5038 5028>,
			<6301 5663 5292 5084 5037 5028>,
			<6285 5663 5289 5083 5037 5028>,
			<6268 5663 5285 5083 5037 5028>,
			<6252 5655 5278 5082 5038 5028>,
			<6234 5644 5271 5082 5038 5029>,
			<6205 5641 5267 5082 5039 5030>,
			<6160 5640 5264 5084 5041 5031>,
			<6142 5639 5262 5085 5042 5032>,
			<6151 5633 5260 5087 5044 5033>,
			<6162 5628 5260 5089 5046 5035>,
			<6149 5634 5266 5092 5048 5036>,
			<6099 5652 5279 5097 5052 5038>,
			<6050 5655 5283 5102 5055 5040>,
			<5991 5599 5281 5108 5057 5042>,
			<5950 5542 5277 5113 5060 5045>,
			<5948 5535 5264 5120 5066 5050>,
			<5948 5532 5242 5127 5073 5055>,
			<5946 5527 5226 5124 5074 5057>,
			<5931 5515 5213 5106 5068 5057>,
			<5918 5504 5204 5088 5060 5056>,
			<5915 5500 5198 5077 5048 5045>,
			<5913 5497 5195 5069 5036 5029>,
			<5914 5492 5194 5068 5034 5026>,
			<5931 5483 5194 5069 5034 5026>,
			<5951 5479 5194 5070 5034 5027>,
			<5971 5489 5196 5072 5036 5028>,
			<5992 5510 5198 5074 5038 5030>,
			<6013 5529 5198 5077 5041 5032>,
			<6035 5551 5198 5080 5045 5035>,
			<6057 5573 5198 5083 5048 5039>,
			<6080 5597 5204 5086 5051 5042>,
			<6103 5623 5214 5087 5053 5045>,
			<6128 5650 5224 5087 5051 5043>,
			<6154 5680 5236 5087 5046 5037>,
			<6181 5712 5248 5086 5042 5033>,
			<6210 5746 5262 5084 5040 5031>,
			<6239 5782 5276 5083 5038 5030>,
			<6272 5821 5290 5084 5040 5032>,
			<6307 5863 5305 5087 5043 5035>,
			<6347 5908 5320 5089 5043 5035>,
			<6392 5961 5341 5090 5040 5031>,
			<6412 5993 5333 5084 5034 5024>,
			<6445 6057 5372 5093 5043 5034>,
			<6490 6113 5398 5100 5050 5042>,
			<6539 6180 5435 5110 5062 5057>,
			<6598 6249 5475 5125 5076 5068>,
			<6663 6326 5522 5134 5077 5066>,
			<6734 6389 5559 5126 5052 5043>,
			<6837 6463 5596 5123 5053 5042>,
			<7006 6589 5691 5142 5061 5047>,
			<7456 6757 5844 5173 5079 5063>,
			<7456 6757 5844 5173 5079 5063>,
			<7456 6757 5844 5173 5079 5063>;
	};

};
